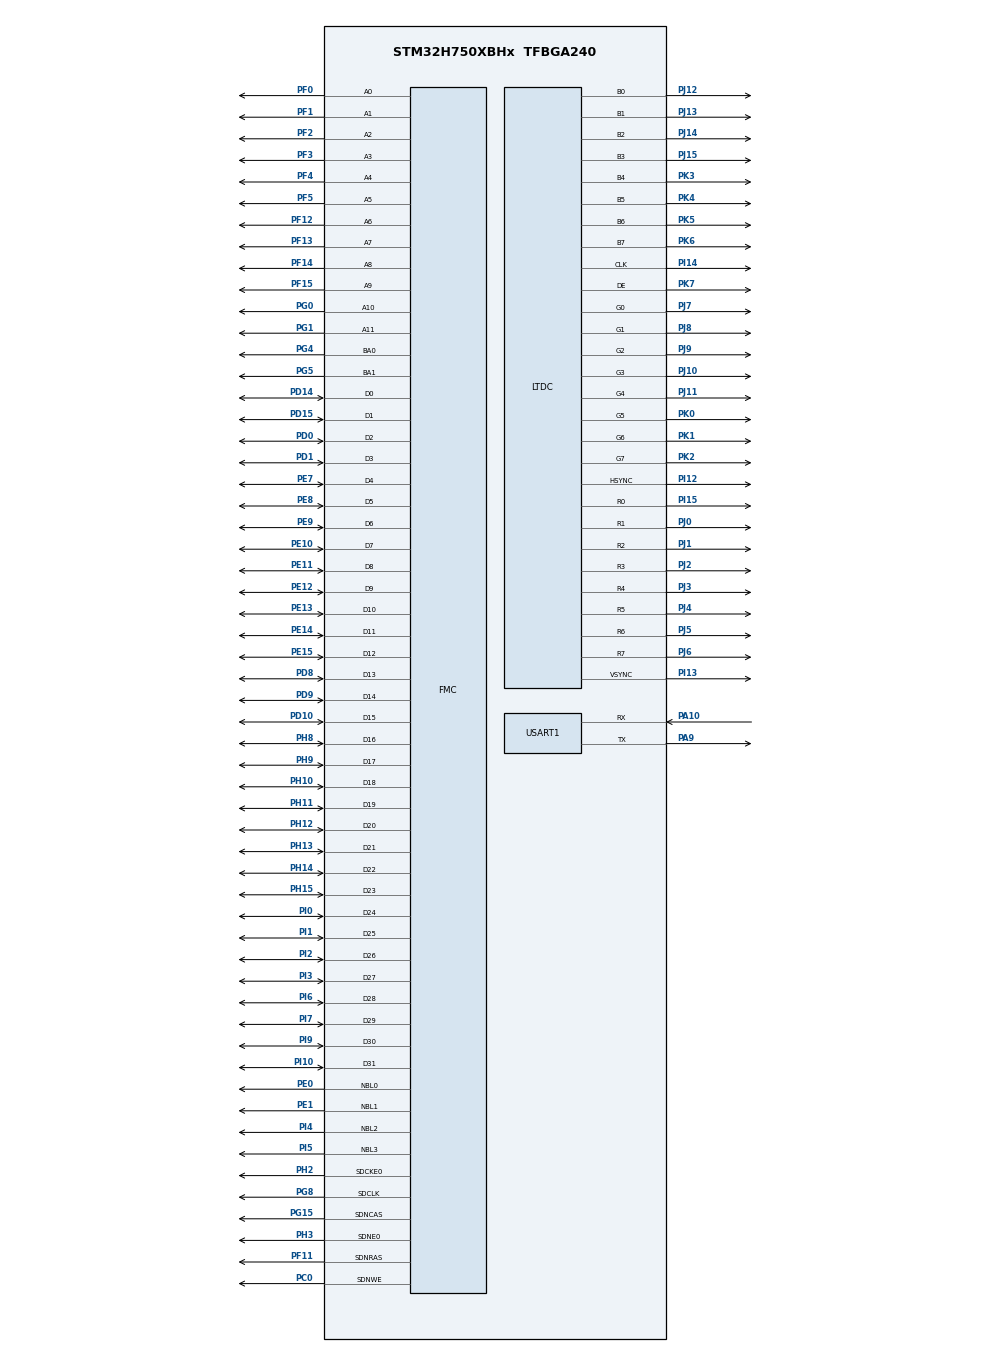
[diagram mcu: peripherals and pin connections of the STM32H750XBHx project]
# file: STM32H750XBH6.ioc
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CORTEX_M7.AccessPermission-Cortex_Memory_Protection_Unit_Region0_Settings=MPU_REGION_FULL_ACCESS
CORTEX_M7.BaseAddress-Cortex_Memory_Protection_Unit_Region0_Settings=0xC0000000
CORTEX_M7.CPU_DCache=Enabled
CORTEX_M7.CPU_ICache=Enabled
CORTEX_M7.Enable-Cortex_Memory_Protection_Unit_Region0_Settings=MPU_REGION_ENABLE
CORTEX_M7.IsBufferable-Cortex_Memory_Protection_Unit_Region0_Settings=MPU_ACCESS_NOT_BUFFERABLE
CORTEX_M7.IsCacheable-Cortex_Memory_Protection_Unit_Region0_Settings=MPU_ACCESS_CACHEABLE
CORTEX_M7.MPU_Control=MPU_PRIVILEGED_DEFAULT
CORTEX_M7.Size-Cortex_Memory_Protection_Unit_Region0_Settings=MPU_REGION_SIZE_16MB
DMA2D.ColorMode=DMA2D_OUTPUT_RGB565
FMC.CASLatency1=FMC_SDRAM_CAS_LATENCY_3
FMC.ColumnBitsNumber1=FMC_SDRAM_COLUMN_BITS_NUM_8
FMC.ExitSelfRefreshDelay1=7
FMC.LoadToActiveDelay1=2
FMC.RCDDelay1=2
FMC.RPDelay1=2
FMC.RPDelay2=2
FMC.ReadBurst1=FMC_SDRAM_RBURST_ENABLE
FMC.ReadBurst2=FMC_SDRAM_RBURST_ENABLE
FMC.RowCycleDelay1=7
FMC.RowCycleDelay2=7
FMC.SDClockPeriod1=FMC_SDRAM_CLOCK_PERIOD_2
FMC.SDClockPeriod2=FMC_SDRAM_CLOCK_PERIOD_2
FMC.SelfRefreshTime1=4
FMC.WriteRecoveryTime1=3
FREERTOS.Tasks01=defaultTask,24,2048,StartDefaultTask,Default,NULL,Dynamic,NULL,NULL;ledTask02,8,128,StartTask02,Default,NULL,Dynamic,NULL,NULL;uartTask03,8,1024,StartTask03,Default,NULL,Dynamic,NULL,NULL
FREERTOS.configUSE_TICK_HOOK=1
LTDC.ActiveW=800
LTDC.Alpha_L0=255
LTDC.FBStartAdress_L0=0xC0000000
LTDC.HBP=80
LTDC.HFP=200
LTDC.HSync=1
LTDC.ImageHeight_L0=480
LTDC.ImageWidth_L0=800
LTDC.Layers=0
LTDC.PixelFormat_L0=LTDC_PIXEL_FORMAT_RGB565
LTDC.VBP=40
LTDC.VFP=22
LTDC.VSync=1
LTDC.WindowX1_L0=800
LTDC.WindowY1_L0=480
Mcu.Family=STM32H7
Mcu.Name=STM32H750XBHx
Mcu.Package=TFBGA240
NVIC.LTDC_IRQn=true\:5\:0\:false\:false\:true\:true\:true\:true\:true
NVIC.PriorityGroup=NVIC_PRIORITYGROUP_4
NVIC.TIM17_IRQn=true\:15\:0\:false\:false\:true\:false\:false\:true\:true
NVIC.TimeBase=TIM17_IRQn
NVIC.TimeBaseIP=TIM17
PA10.GPIO_Speed=GPIO_SPEED_FREQ_VERY_HIGH
PA10.Mode=Asynchronous
PA10.Signal=USART1_RX
PA9.GPIO_Speed=GPIO_SPEED_FREQ_VERY_HIGH
PA9.Mode=Asynchronous
PA9.Signal=USART1_TX
PC0.Signal=FMC_SDNWE
PD0.Signal=FMC_D2_DA2
PD1.Signal=FMC_D3_DA3
PD10.Signal=FMC_D15_DA15
PD14.Signal=FMC_D0_DA0
PD15.Signal=FMC_D1_DA1
PD8.Signal=FMC_D13_DA13
PD9.Signal=FMC_D14_DA14
PE0.Signal=FMC_NBL0
PE1.Signal=FMC_NBL1
PE10.Signal=FMC_D7_DA7
PE11.Signal=FMC_D8_DA8
PE12.Signal=FMC_D9_DA9
PE13.Signal=FMC_D10_DA10
PE14.Signal=FMC_D11_DA11
PE15.Signal=FMC_D12_DA12
PE7.Signal=FMC_D4_DA4
PE8.Signal=FMC_D5_DA5
PE9.Signal=FMC_D6_DA6
PF0.Signal=FMC_A0
PF1.Signal=FMC_A1
PF11.Signal=FMC_SDNRAS
PF12.Signal=FMC_A6
PF13.Signal=FMC_A7
PF14.Signal=FMC_A8
PF15.Signal=FMC_A9
PF2.Signal=FMC_A2
PF3.Signal=FMC_A3
PF4.Signal=FMC_A4
PF5.Signal=FMC_A5
PG0.Signal=FMC_A10
PG1.Signal=FMC_A11
PG15.Signal=FMC_SDNCAS
PG4.Signal=FMC_A14_BA0
PG5.Signal=FMC_A15_BA1
PG8.Signal=FMC_SDCLK
PH0-OSC_IN\ (PH0).Mode=HSE-External-Oscillator
PH0-OSC_IN\ (PH0).Signal=RCC_OSC_IN
PH1-OSC_OUT\ (PH1).Mode=HSE-External-Oscillator
PH1-OSC_OUT\ (PH1).Signal=RCC_OSC_OUT
PH10.Signal=FMC_D18
PH11.Signal=FMC_D19
PH12.Signal=FMC_D20
PH13.Signal=FMC_D21
PH14.Signal=FMC_D22
PH15.Signal=FMC_D23
PH2.Mode=SdramChipSelect1_1
PH2.Signal=FMC_SDCKE0
PH3.Mode=SdramChipSelect1_1
PH3.Signal=FMC_SDNE0
PH8.Signal=FMC_D16
PH9.Signal=FMC_D17
PI0.Signal=FMC_D24
PI1.Signal=FMC_D25
PI10.Signal=FMC_D31
PI12.GPIO_Speed=GPIO_SPEED_FREQ_VERY_HIGH
PI12.Mode=RGB888
PI12.Signal=LTDC_HSYNC
PI13.GPIO_Speed=GPIO_SPEED_FREQ_VERY_HIGH
PI13.Mode=RGB888
PI13.Signal=LTDC_VSYNC
PI14.GPIO_Speed=GPIO_SPEED_FREQ_VERY_HIGH
PI14.Mode=RGB888
PI14.Signal=LTDC_CLK
PI15.GPIO_Speed=GPIO_SPEED_FREQ_VERY_HIGH
PI15.Mode=RGB888
PI15.Signal=LTDC_R0
PI2.Signal=FMC_D26
PI3.Signal=FMC_D27
PI4.Signal=FMC_NBL2
PI5.Signal=FMC_NBL3
PI6.Signal=FMC_D28
PI7.Signal=FMC_D29
PI9.Signal=FMC_D30
PJ0.GPIO_Speed=GPIO_SPEED_FREQ_VERY_HIGH
PJ0.Mode=RGB888
PJ0.Signal=LTDC_R1
PJ1.GPIO_Speed=GPIO_SPEED_FREQ_VERY_HIGH
PJ1.Mode=RGB888
PJ1.Signal=LTDC_R2
PJ10.GPIO_Speed=GPIO_SPEED_FREQ_VERY_HIGH
PJ10.Mode=RGB888
PJ10.Signal=LTDC_G3
PJ11.GPIO_Speed=GPIO_SPEED_FREQ_VERY_HIGH
PJ11.Mode=RGB888
PJ11.Signal=LTDC_G4
PJ12.GPIO_Speed=GPIO_SPEED_FREQ_VERY_HIGH
PJ12.Mode=RGB888
PJ12.Signal=LTDC_B0
PJ13.GPIO_Speed=GPIO_SPEED_FREQ_VERY_HIGH
PJ13.Mode=RGB888
PJ13.Signal=LTDC_B1
PJ14.GPIO_Speed=GPIO_SPEED_FREQ_VERY_HIGH
PJ14.Mode=RGB888
PJ14.Signal=LTDC_B2
PJ15.GPIO_Speed=GPIO_SPEED_FREQ_VERY_HIGH
PJ15.Mode=RGB888
PJ15.Signal=LTDC_B3
PJ2.GPIO_Speed=GPIO_SPEED_FREQ_VERY_HIGH
PJ2.Mode=RGB888
PJ2.Signal=LTDC_R3
PJ3.GPIO_Speed=GPIO_SPEED_FREQ_VERY_HIGH
PJ3.Mode=RGB888
PJ3.Signal=LTDC_R4
PJ4.GPIO_Speed=GPIO_SPEED_FREQ_VERY_HIGH
PJ4.Mode=RGB888
PJ4.Signal=LTDC_R5
PJ5.GPIO_Speed=GPIO_SPEED_FREQ_VERY_HIGH
PJ5.Mode=RGB888
PJ5.Signal=LTDC_R6
PJ6.GPIO_Speed=GPIO_SPEED_FREQ_VERY_HIGH
PJ6.Mode=RGB888
PJ6.Signal=LTDC_R7
PJ7.GPIO_Speed=GPIO_SPEED_FREQ_VERY_HIGH
PJ7.Mode=RGB888
PJ7.Signal=LTDC_G0
PJ8.GPIO_Speed=GPIO_SPEED_FREQ_VERY_HIGH
PJ8.Mode=RGB888
PJ8.Signal=LTDC_G1
PJ9.GPIO_Speed=GPIO_SPEED_FREQ_VERY_HIGH
PJ9.Mode=RGB888
PJ9.Signal=LTDC_G2
PK0.GPIO_Speed=GPIO_SPEED_FREQ_VERY_HIGH
PK0.Mode=RGB888
PK0.Signal=LTDC_G5
PK1.GPIO_Speed=GPIO_SPEED_FREQ_VERY_HIGH
PK1.Mode=RGB888
PK1.Signal=LTDC_G6
PK2.GPIO_Speed=GPIO_SPEED_FREQ_VERY_HIGH
PK2.Mode=RGB888
PK2.Signal=LTDC_G7
PK3.GPIO_Speed=GPIO_SPEED_FREQ_VERY_HIGH
PK3.Mode=RGB888
PK3.Signal=LTDC_B4
PK4.GPIO_Speed=GPIO_SPEED_FREQ_VERY_HIGH
PK4.Mode=RGB888
PK4.Signal=LTDC_B5
PK5.GPIO_Speed=GPIO_SPEED_FREQ_VERY_HIGH
PK5.Mode=RGB888
PK5.Signal=LTDC_B6
PK6.GPIO_Speed=GPIO_SPEED_FREQ_VERY_HIGH
PK6.Mode=RGB888
PK6.Signal=LTDC_B7
PK7.GPIO_Speed=GPIO_SPEED_FREQ_VERY_HIGH
PK7.Mode=RGB888
PK7.Signal=LTDC_DE
ProjectManager.HeapSize=0x2000
ProjectManager.StackSize=0x2000
ProjectManager.TargetToolchain=MDK-ARM V5.32
RCC.ADCFreq_Value=50390625
RCC.APB1Freq_Value=120000000
RCC.APB2Freq_Value=120000000
RCC.APB3Freq_Value=120000000
RCC.APB4Freq_Value=120000000
RCC.CortexFreq_Value=480000000
RCC.D1PPRE=RCC_APB3_DIV2
RCC.D2PPRE1=RCC_APB1_DIV2
RCC.D2PPRE2=RCC_APB2_DIV2
RCC.D3PPRE=RCC_APB4_DIV2
RCC.DIVM1=5
RCC.DIVM3=25
RCC.DIVN1=192
RCC.DIVN3=330
RCC.DIVR3=10
RCC.HCLKFreq_Value=240000000
RCC.HPRE=RCC_HCLK_DIV2
RCC.PLLSourceVirtual=RCC_PLLSOURCE_HSE
RCC.SYSCLKFreq_VALUE=480000000
RCC.SYSCLKSource=RCC_SYSCLKSOURCE_PLLCLK
RCC.USBFreq_Value=480000000
SH.FMC_A0.0=FMC_A0,12b-sda1
SH.FMC_A1.0=FMC_A1,12b-sda1
SH.FMC_A10.0=FMC_A10,12b-sda1
SH.FMC_A11.0=FMC_A11,12b-sda1
SH.FMC_A14_BA0.0=FMC_BA0,FourSdramBanks1
SH.FMC_A15_BA1.0=FMC_BA1,FourSdramBanks1
SH.FMC_A2.0=FMC_A2,12b-sda1
SH.FMC_A3.0=FMC_A3,12b-sda1
SH.FMC_A4.0=FMC_A4,12b-sda1
SH.FMC_A5.0=FMC_A5,12b-sda1
SH.FMC_A6.0=FMC_A6,12b-sda1
SH.FMC_A7.0=FMC_A7,12b-sda1
SH.FMC_A8.0=FMC_A8,12b-sda1
SH.FMC_A9.0=FMC_A9,12b-sda1
SH.FMC_D0_DA0.0=FMC_D0,sd-32b-d1
SH.FMC_D10_DA10.0=FMC_D10,sd-32b-d1
SH.FMC_D11_DA11.0=FMC_D11,sd-32b-d1
SH.FMC_D12_DA12.0=FMC_D12,sd-32b-d1
SH.FMC_D13_DA13.0=FMC_D13,sd-32b-d1
SH.FMC_D14_DA14.0=FMC_D14,sd-32b-d1
SH.FMC_D15_DA15.0=FMC_D15,sd-32b-d1
SH.FMC_D16.0=FMC_D16,sd-32b-d1
SH.FMC_D17.0=FMC_D17,sd-32b-d1
SH.FMC_D18.0=FMC_D18,sd-32b-d1
SH.FMC_D19.0=FMC_D19,sd-32b-d1
SH.FMC_D1_DA1.0=FMC_D1,sd-32b-d1
SH.FMC_D20.0=FMC_D20,sd-32b-d1
SH.FMC_D21.0=FMC_D21,sd-32b-d1
SH.FMC_D22.0=FMC_D22,sd-32b-d1
SH.FMC_D23.0=FMC_D23,sd-32b-d1
SH.FMC_D24.0=FMC_D24,sd-32b-d1
SH.FMC_D25.0=FMC_D25,sd-32b-d1
SH.FMC_D26.0=FMC_D26,sd-32b-d1
SH.FMC_D27.0=FMC_D27,sd-32b-d1
SH.FMC_D28.0=FMC_D28,sd-32b-d1
SH.FMC_D29.0=FMC_D29,sd-32b-d1
SH.FMC_D2_DA2.0=FMC_D2,sd-32b-d1
SH.FMC_D30.0=FMC_D30,sd-32b-d1
SH.FMC_D31.0=FMC_D31,sd-32b-d1
SH.FMC_D3_DA3.0=FMC_D3,sd-32b-d1
SH.FMC_D4_DA4.0=FMC_D4,sd-32b-d1
SH.FMC_D5_DA5.0=FMC_D5,sd-32b-d1
SH.FMC_D6_DA6.0=FMC_D6,sd-32b-d1
SH.FMC_D7_DA7.0=FMC_D7,sd-32b-d1
SH.FMC_D8_DA8.0=FMC_D8,sd-32b-d1
SH.FMC_D9_DA9.0=FMC_D9,sd-32b-d1
SH.FMC_NBL0.0=FMC_NBL0,Sd4ByteEnable1
SH.FMC_NBL1.0=FMC_NBL1,Sd4ByteEnable1
SH.FMC_NBL2.0=FMC_NBL2,Sd4ByteEnable1
SH.FMC_NBL3.0=FMC_NBL3,Sd4ByteEnable1
SH.FMC_SDCLK.0=FMC_SDCLK,12b-sda1
SH.FMC_SDNCAS.0=FMC_SDNCAS,12b-sda1
SH.FMC_SDNRAS.0=FMC_SDNRAS,12b-sda1
SH.FMC_SDNWE.0=FMC_SDNWE,12b-sda1
USART1.VirtualMode-Asynchronous=VM_ASYNC
VP_DMA2D_VS_DMA2D.Mode=DMA2D_Activate
VP_FREERTOS_VS_CMSIS_V2.Mode=CMSIS_V2
VP_SYS_VS_tim17.Mode=TIM17
board=custom

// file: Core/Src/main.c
/* USER CODE BEGIN Header */
/**
  ******************************************************************************
  * @file           : main.c
  * @brief          : Main program body
  ******************************************************************************
  * @attention
  *
  * Copyright (c) 2024 STMicroelectronics.
  * All rights reserved.
  *
  * This software is licensed under terms that can be found in the LICENSE file
  * in the root directory of this software component.
  * If no LICENSE file comes with this software, it is provided AS-IS.
  *
  ******************************************************************************
  */
/* USER CODE END Header */
#include "main.h"
#include "cmsis_os.h"

/* USER CODE BEGIN Includes */
#include "led.h"
#include "usart.h"
#include "sdram.h"
#include "lcd_rgb.h"
#include "touch_800x480.h"
#include "lvgl.h"
#include "lv_port_disp_template.h"
#include "lv_port_indev_template.h"
#include "lv_demo_widgets.h"
/* USER CODE END Includes */

DMA2D_HandleTypeDef hdma2d;

LTDC_HandleTypeDef hltdc;

UART_HandleTypeDef huart1;

SDRAM_HandleTypeDef hsdram1;

/* Definitions for defaultTask */
osThreadId_t defaultTaskHandle;
const osThreadAttr_t defaultTask_attributes = {
  .name = "defaultTask",
  .stack_size = 2048 * 4,
  .priority = (osPriority_t) osPriorityNormal,
};
/* Definitions for ledTask02 */
osThreadId_t ledTask02Handle;
const osThreadAttr_t ledTask02_attributes = {
  .name = "ledTask02",
  .stack_size = 128 * 4,
  .priority = (osPriority_t) osPriorityLow,
};
/* Definitions for uartTask03 */
osThreadId_t uartTask03Handle;
const osThreadAttr_t uartTask03_attributes = {
  .name = "uartTask03",
  .stack_size = 1024 * 4,
  .priority = (osPriority_t) osPriorityLow,
};
/* USER CODE BEGIN PV */
osMutexId_t mutex_id;

const osMutexAttr_t Thread_Mutex_attr = {
  "myThreadMutex",     // human readable mutex name
  osMutexPrioInherit,  // attr_bits
  NULL,                // memory for control block
  0U                   // size for control block
};

/* USER CODE END PV */

void SystemClock_Config(void);
static void MPU_Config(void);
static void MX_GPIO_Init(void);
static void MX_USART1_UART_Init(void);
static void MX_FMC_Init(void);
static void MX_DMA2D_Init(void);
static void MX_LTDC_Init(void);
void StartDefaultTask(void *argument);
void StartTask02(void *argument);
void StartTask03(void *argument);

int main(void)
{

  /* MPU Configuration--------------------------------------------------------*/
  MPU_Config();
/* Enable the CPU Cache */

  /* Enable I-Cache---------------------------------------------------------*/
  SCB_EnableICache();

  /* Enable D-Cache---------------------------------------------------------*/
  SCB_EnableDCache();

  /* MCU Configuration--------------------------------------------------------*/

  /* Reset of all peripherals, Initializes the Flash interface and the Systick. */
  HAL_Init();

  /* Configure the system clock */
  SystemClock_Config();

  /* Initialize all configured peripherals */
  MX_GPIO_Init();
  MX_USART1_UART_Init();
  MX_FMC_Init();
  MX_DMA2D_Init();
  MX_LTDC_Init();
  /* USER CODE BEGIN 2 */
	LED_Init();					// 初始化LED引脚
	SDRAM_Initialization_Sequence(&hsdram1);	// 配置SDRAM相关时序和控制方式

	LCD_RGB_Init();		// 初始化屏幕
	Touch_Init();				// 触摸屏初始化

  /* USER CODE END 2 */

  /* Init scheduler */
  osKernelInitialize();

  /* Create the thread(s) */
  /* creation of defaultTask */
  defaultTaskHandle = osThreadNew(StartDefaultTask, NULL, &defaultTask_attributes);

  /* creation of ledTask02 */
  ledTask02Handle = osThreadNew(StartTask02, NULL, &ledTask02_attributes);

  /* creation of uartTask03 */
  uartTask03Handle = osThreadNew(StartTask03, NULL, &uartTask03_attributes);

  /* USER CODE BEGIN RTOS_THREADS */
  /* add threads, ... */
 	mutex_id = osMutexNew(&Thread_Mutex_attr);

  /* USER CODE END RTOS_THREADS */

  /* Start scheduler */
  osKernelStart();

  /* We should never get here as control is now taken by the scheduler */
  /* Infinite loop */
  while (1)
  {

  }
}

void SystemClock_Config(void)
{
  RCC_OscInitTypeDef RCC_OscInitStruct = {0};
  RCC_ClkInitTypeDef RCC_ClkInitStruct = {0};

  /** Supply configuration update enable
  */
  HAL_PWREx_ConfigSupply(PWR_LDO_SUPPLY);

  /** Configure the main internal regulator output voltage
  */
  __HAL_PWR_VOLTAGESCALING_CONFIG(PWR_REGULATOR_VOLTAGE_SCALE1);

  while(!__HAL_PWR_GET_FLAG(PWR_FLAG_VOSRDY)) {}

  __HAL_RCC_SYSCFG_CLK_ENABLE();
  __HAL_PWR_VOLTAGESCALING_CONFIG(PWR_REGULATOR_VOLTAGE_SCALE0);

  while(!__HAL_PWR_GET_FLAG(PWR_FLAG_VOSRDY)) {}

  /** Initializes the RCC Oscillators according to the specified parameters
  * in the RCC_OscInitTypeDef structure.
  */
  RCC_OscInitStruct.OscillatorType = RCC_OSCILLATORTYPE_HSE;
  RCC_OscInitStruct.HSEState = RCC_HSE_ON;
  RCC_OscInitStruct.PLL.PLLState = RCC_PLL_ON;
  RCC_OscInitStruct.PLL.PLLSource = RCC_PLLSOURCE_HSE;
  RCC_OscInitStruct.PLL.PLLM = 5;
  RCC_OscInitStruct.PLL.PLLN = 192;
  RCC_OscInitStruct.PLL.PLLP = 2;
  RCC_OscInitStruct.PLL.PLLQ = 2;
  RCC_OscInitStruct.PLL.PLLR = 2;
  RCC_OscInitStruct.PLL.PLLRGE = RCC_PLL1VCIRANGE_2;
  RCC_OscInitStruct.PLL.PLLVCOSEL = RCC_PLL1VCOWIDE;
  RCC_OscInitStruct.PLL.PLLFRACN = 0;
  if (HAL_RCC_OscConfig(&RCC_OscInitStruct) != HAL_OK)
  {
    Error_Handler();
  }

  /** Initializes the CPU, AHB and APB buses clocks
  */
  RCC_ClkInitStruct.ClockType = RCC_CLOCKTYPE_HCLK|RCC_CLOCKTYPE_SYSCLK
                              |RCC_CLOCKTYPE_PCLK1|RCC_CLOCKTYPE_PCLK2
                              |RCC_CLOCKTYPE_D3PCLK1|RCC_CLOCKTYPE_D1PCLK1;
  RCC_ClkInitStruct.SYSCLKSource = RCC_SYSCLKSOURCE_PLLCLK;
  RCC_ClkInitStruct.SYSCLKDivider = RCC_SYSCLK_DIV1;
  RCC_ClkInitStruct.AHBCLKDivider = RCC_HCLK_DIV2;
  RCC_ClkInitStruct.APB3CLKDivider = RCC_APB3_DIV2;
  RCC_ClkInitStruct.APB1CLKDivider = RCC_APB1_DIV2;
  RCC_ClkInitStruct.APB2CLKDivider = RCC_APB2_DIV2;
  RCC_ClkInitStruct.APB4CLKDivider = RCC_APB4_DIV2;

  if (HAL_RCC_ClockConfig(&RCC_ClkInitStruct, FLASH_LATENCY_4) != HAL_OK)
  {
    Error_Handler();
  }
}

static void MX_DMA2D_Init(void)
{

  hdma2d.Instance = DMA2D;
  hdma2d.Init.Mode = DMA2D_M2M;
  hdma2d.Init.ColorMode = DMA2D_OUTPUT_RGB565;
  hdma2d.Init.OutputOffset = 0;
  hdma2d.LayerCfg[1].InputOffset = 0;
  hdma2d.LayerCfg[1].InputColorMode = DMA2D_INPUT_RGB565;
  hdma2d.LayerCfg[1].AlphaMode = DMA2D_NO_MODIF_ALPHA;
  hdma2d.LayerCfg[1].InputAlpha = 0;
  hdma2d.LayerCfg[1].AlphaInverted = DMA2D_REGULAR_ALPHA;
  hdma2d.LayerCfg[1].RedBlueSwap = DMA2D_RB_REGULAR;
  hdma2d.LayerCfg[1].ChromaSubSampling = DMA2D_NO_CSS;
  if (HAL_DMA2D_Init(&hdma2d) != HAL_OK)
  {
    Error_Handler();
  }
  if (HAL_DMA2D_ConfigLayer(&hdma2d, 1) != HAL_OK)
  {
    Error_Handler();
  }

}

static void MX_LTDC_Init(void)
{

  LTDC_LayerCfgTypeDef pLayerCfg = {0};

  hltdc.Instance = LTDC;
  hltdc.Init.HSPolarity = LTDC_HSPOLARITY_AL;
  hltdc.Init.VSPolarity = LTDC_VSPOLARITY_AL;
  hltdc.Init.DEPolarity = LTDC_DEPOLARITY_AL;
  hltdc.Init.PCPolarity = LTDC_PCPOLARITY_IPC;
  hltdc.Init.HorizontalSync = 0;
  hltdc.Init.VerticalSync = 0;
  hltdc.Init.AccumulatedHBP = 80;
  hltdc.Init.AccumulatedVBP = 40;
  hltdc.Init.AccumulatedActiveW = 880;
  hltdc.Init.AccumulatedActiveH = 520;
  hltdc.Init.TotalWidth = 1080;
  hltdc.Init.TotalHeigh = 542;
  hltdc.Init.Backcolor.Blue = 0;
  hltdc.Init.Backcolor.Green = 0;
  hltdc.Init.Backcolor.Red = 0;
  if (HAL_LTDC_Init(&hltdc) != HAL_OK)
  {
    Error_Handler();
  }
  pLayerCfg.WindowX0 = 0;
  pLayerCfg.WindowX1 = 800;
  pLayerCfg.WindowY0 = 0;
  pLayerCfg.WindowY1 = 480;
  pLayerCfg.PixelFormat = LTDC_PIXEL_FORMAT_RGB565;
  pLayerCfg.Alpha = 255;
  pLayerCfg.Alpha0 = 0;
  pLayerCfg.BlendingFactor1 = LTDC_BLENDING_FACTOR1_CA;
  pLayerCfg.BlendingFactor2 = LTDC_BLENDING_FACTOR2_CA;
  pLayerCfg.FBStartAdress = 0xC0000000;
  pLayerCfg.ImageWidth = 800;
  pLayerCfg.ImageHeight = 480;
  pLayerCfg.Backcolor.Blue = 0;
  pLayerCfg.Backcolor.Green = 0;
  pLayerCfg.Backcolor.Red = 0;
  if (HAL_LTDC_ConfigLayer(&hltdc, &pLayerCfg, 0) != HAL_OK)
  {
    Error_Handler();
  }

}

static void MX_USART1_UART_Init(void)
{

  huart1.Instance = USART1;
  huart1.Init.BaudRate = 115200;
  huart1.Init.WordLength = UART_WORDLENGTH_8B;
  huart1.Init.StopBits = UART_STOPBITS_1;
  huart1.Init.Parity = UART_PARITY_NONE;
  huart1.Init.Mode = UART_MODE_TX_RX;
  huart1.Init.HwFlowCtl = UART_HWCONTROL_NONE;
  huart1.Init.OverSampling = UART_OVERSAMPLING_16;
  huart1.Init.OneBitSampling = UART_ONE_BIT_SAMPLE_DISABLE;
  huart1.Init.ClockPrescaler = UART_PRESCALER_DIV1;
  huart1.AdvancedInit.AdvFeatureInit = UART_ADVFEATURE_NO_INIT;
  if (HAL_UART_Init(&huart1) != HAL_OK)
  {
    Error_Handler();
  }
  if (HAL_UARTEx_SetTxFifoThreshold(&huart1, UART_TXFIFO_THRESHOLD_1_8) != HAL_OK)
  {
    Error_Handler();
  }
  if (HAL_UARTEx_SetRxFifoThreshold(&huart1, UART_RXFIFO_THRESHOLD_1_8) != HAL_OK)
  {
    Error_Handler();
  }
  if (HAL_UARTEx_DisableFifoMode(&huart1) != HAL_OK)
  {
    Error_Handler();
  }

}

/* FMC initialization function */
static void MX_FMC_Init(void)
{

  FMC_SDRAM_TimingTypeDef SdramTiming = {0};

  /** Perform the SDRAM1 memory initialization sequence
  */
  hsdram1.Instance = FMC_SDRAM_DEVICE;
  /* hsdram1.Init */
  hsdram1.Init.SDBank = FMC_SDRAM_BANK1;
  hsdram1.Init.ColumnBitsNumber = FMC_SDRAM_COLUMN_BITS_NUM_8;
  hsdram1.Init.RowBitsNumber = FMC_SDRAM_ROW_BITS_NUM_12;
  hsdram1.Init.MemoryDataWidth = FMC_SDRAM_MEM_BUS_WIDTH_32;
  hsdram1.Init.InternalBankNumber = FMC_SDRAM_INTERN_BANKS_NUM_4;
  hsdram1.Init.CASLatency = FMC_SDRAM_CAS_LATENCY_3;
  hsdram1.Init.WriteProtection = FMC_SDRAM_WRITE_PROTECTION_DISABLE;
  hsdram1.Init.SDClockPeriod = FMC_SDRAM_CLOCK_PERIOD_2;
  hsdram1.Init.ReadBurst = FMC_SDRAM_RBURST_ENABLE;
  hsdram1.Init.ReadPipeDelay = FMC_SDRAM_RPIPE_DELAY_0;
  /* SdramTiming */
  SdramTiming.LoadToActiveDelay = 2;
  SdramTiming.ExitSelfRefreshDelay = 7;
  SdramTiming.SelfRefreshTime = 4;
  SdramTiming.RowCycleDelay = 7;
  SdramTiming.WriteRecoveryTime = 3;
  SdramTiming.RPDelay = 2;
  SdramTiming.RCDDelay = 2;

  if (HAL_SDRAM_Init(&hsdram1, &SdramTiming) != HAL_OK)
  {
    Error_Handler( );
  }

}

static void MX_GPIO_Init(void)
{

  /* GPIO Ports Clock Enable */
  __HAL_RCC_GPIOI_CLK_ENABLE();
  __HAL_RCC_GPIOK_CLK_ENABLE();
  __HAL_RCC_GPIOE_CLK_ENABLE();
  __HAL_RCC_GPIOJ_CLK_ENABLE();
  __HAL_RCC_GPIOH_CLK_ENABLE();
  __HAL_RCC_GPIOG_CLK_ENABLE();
  __HAL_RCC_GPIOD_CLK_ENABLE();
  __HAL_RCC_GPIOA_CLK_ENABLE();
  __HAL_RCC_GPIOF_CLK_ENABLE();
  __HAL_RCC_GPIOC_CLK_ENABLE();

}

void StartDefaultTask(void *argument)
{
  /* USER CODE BEGIN 5 */
	uint32_t  time;

	lv_init();					//	LVGL初始化
	lv_port_disp_init();		//	LVGL显示接口初始化
	lv_port_indev_init();	// LVGL触摸接口初始化

	lv_demo_widgets();   // 运行官方例程 lv_demo_benchmark ，进行基准性能测试

  /* Infinite loop */
  for(;;)
  {
		osMutexAcquire(mutex_id, osWaitForever);

		lv_task_handler();	// 如果在多任务中需要进行LVGL相关操作，需要考虑加互斥锁，具体可以参考LVGL官方的介绍

		osMutexRelease(mutex_id);

	  	Touch_Scan();	// 触摸扫描

		osDelay(LV_DISP_DEF_REFR_PERIOD);	// 延时不能小于 LV_DISP_DEF_REFR_PERIOD，否则会闪烁，另外触摸扫描的延时也不能太低
  }
  /* USER CODE END 5 */
}

void StartTask02(void *argument)
{
  /* USER CODE BEGIN StartTask02 */
  /* Infinite loop */
  for(;;)
  {
	  LED1_Toggle;
     osDelay(100);
  }
  /* USER CODE END StartTask02 */
}

void StartTask03(void *argument)
{
  /* USER CODE BEGIN StartTask03 */
  /* Infinite loop */
  for(;;)
  {
		osDelay(10);
  }
  /* USER CODE END StartTask03 */
}

/* MPU Configuration */

void MPU_Config(void)
{
  MPU_Region_InitTypeDef MPU_InitStruct = {0};

  /* Disables the MPU */
  HAL_MPU_Disable();

  /** Initializes and configures the Region and the memory to be protected
  */
  MPU_InitStruct.Enable = MPU_REGION_ENABLE;
  MPU_InitStruct.Number = MPU_REGION_NUMBER0;
  MPU_InitStruct.BaseAddress = 0xC0000000;
  MPU_InitStruct.Size = MPU_REGION_SIZE_16MB;
  MPU_InitStruct.SubRegionDisable = 0x0;
  MPU_InitStruct.TypeExtField = MPU_TEX_LEVEL0;
  MPU_InitStruct.AccessPermission = MPU_REGION_FULL_ACCESS;
  MPU_InitStruct.DisableExec = MPU_INSTRUCTION_ACCESS_ENABLE;
  MPU_InitStruct.IsShareable = MPU_ACCESS_NOT_SHAREABLE;
  MPU_InitStruct.IsCacheable = MPU_ACCESS_CACHEABLE;
  MPU_InitStruct.IsBufferable = MPU_ACCESS_NOT_BUFFERABLE;

  HAL_MPU_ConfigRegion(&MPU_InitStruct);
  /* Enables the MPU */
  HAL_MPU_Enable(MPU_PRIVILEGED_DEFAULT);

}

void HAL_TIM_PeriodElapsedCallback(TIM_HandleTypeDef *htim)
{
  if (htim->Instance == TIM17) {
    HAL_IncTick();
  }
}

void Error_Handler(void)
{
  __disable_irq();
  while (1)
  {
  }
}
